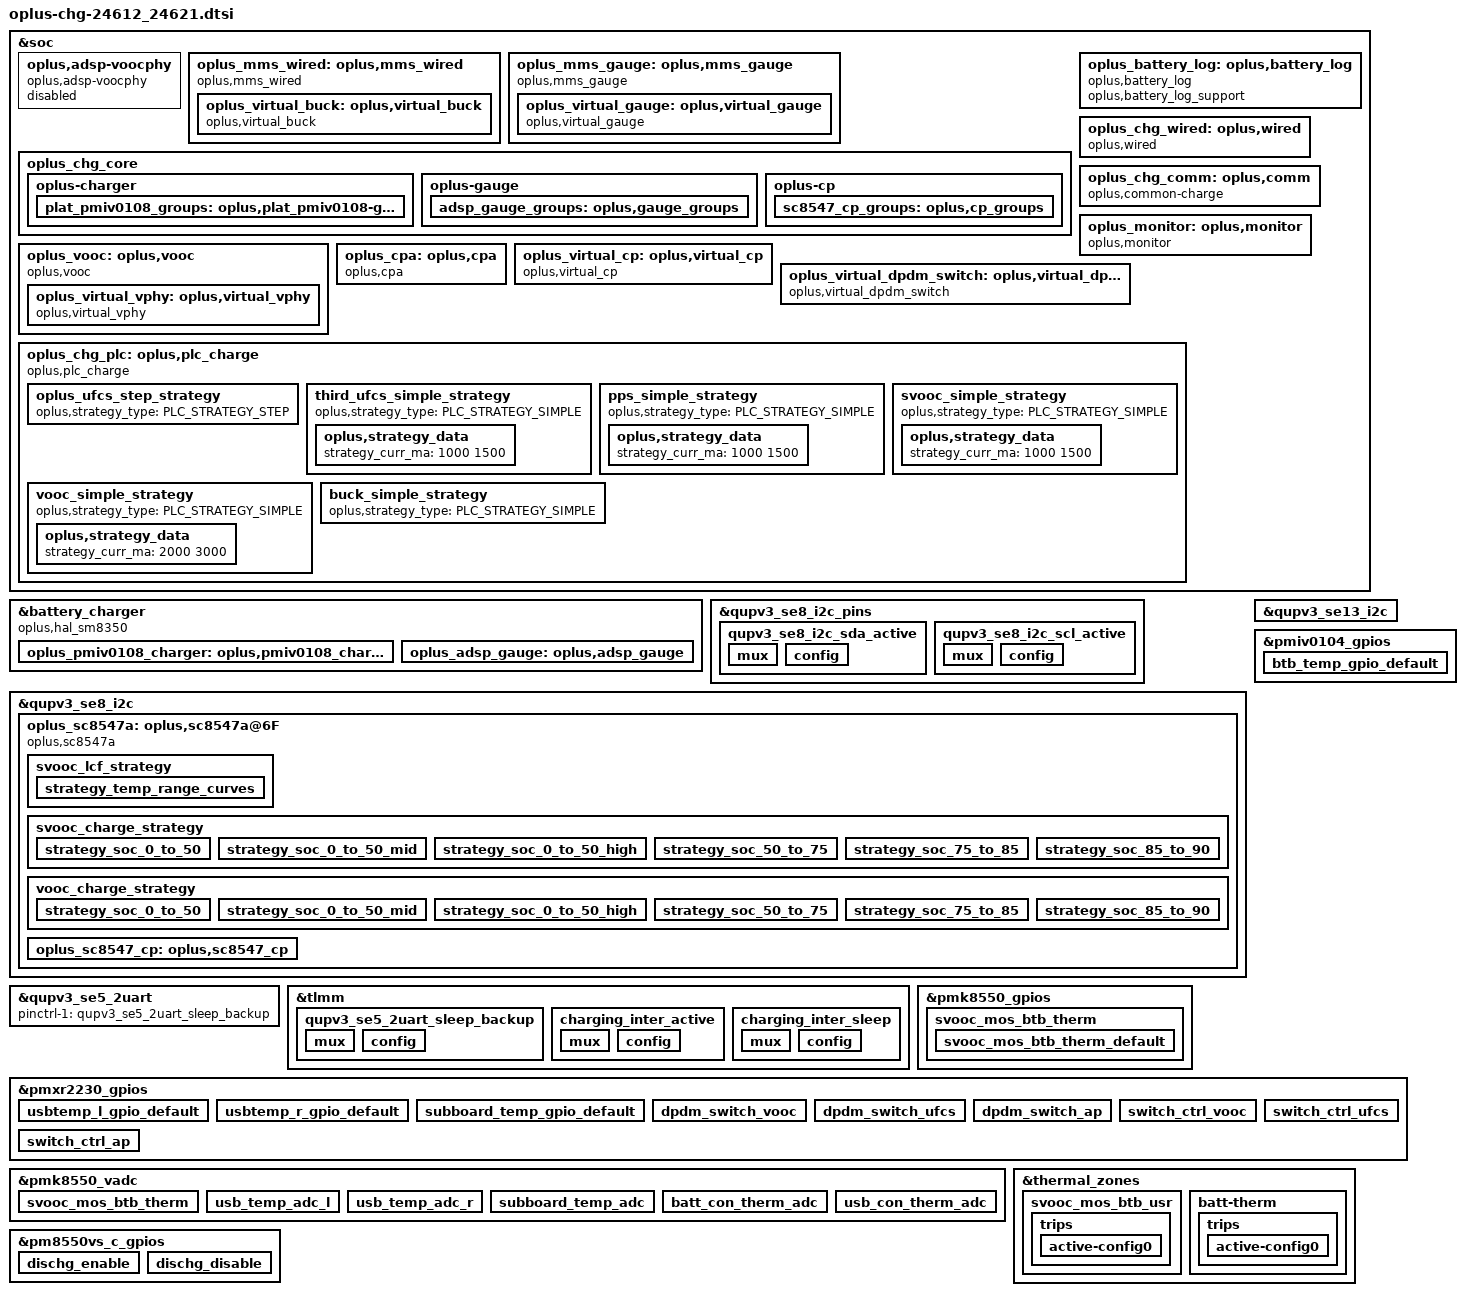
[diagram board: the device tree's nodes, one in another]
//ifdef OPLUS_FEATURE_CHG_BASIC
//BSP.CHG.Basic, 2024/10/16,  Add for charging
#include <dt-bindings/iio/qcom,spmi-adc5-gen3-pmxr2230.h>
#include <dt-bindings/iio/qcom,spmi-adc5-gen3-pmiv0104.h>
#include <dt-bindings/iio/qcom,spmi-adc5-gen3-pmk8550.h>

#include "oplus-chg-8650.h.dtsi"
#include "pps/oplus-chg-dongfeng-pps.dtsi"
#include "ufcs/oplus-chg-dongfeng-ufcs.dtsi"

&soc {
	oplus,adsp-voocphy {
		status = "disabled";
		compatible = "oplus,adsp-voocphy";
	};

	oplus_mms_wired: oplus,mms_wired {
		compatible = "oplus,mms_wired";
		oplus,buck_ic = <&oplus_virtual_buck>;
		oplus,voocphy_ic = <&oplus_virtual_vphy>;
		oplus,usbtemp_batttemp_gap = <10>;
		oplus,adc_info_name = "855";
		oplus,topic-update-interval = <5000>;

		high-temp-scheme;
		oplus,support_usbtemp_protect_v2;
		oplus_spec,usbtemp_batt_temp_low = <50>;
		oplus_spec,usbtemp_batt_temp_high = <50>;
		oplus_spec,usbtemp_batt_temp_over_hot = <60>;
		oplus_spec,usbtemp_ntc_temp_low = <57>;
		oplus_spec,usbtemp_ntc_temp_high = <69>;
		oplus_spec,usbtemp_temp_gap_low_with_batt_temp = <7>;
		oplus_spec,usbtemp_temp_gap_with_batt_temp_in_over_hot = <15>;
		oplus_spec,usbtemp_temp_gap_high_with_batt_temp = <12>;
		oplus_spec,usbtemp_temp_gap_low_without_batt_temp = <12>;
		oplus_spec,usbtemp_temp_gap_high_without_batt_temp = <24>;
		oplus_spec,usbtemp_rise_fast_temp_low = <3>;
		oplus_spec,usbtemp_rise_fast_temp_high = <3>;
		oplus_spec,usbtemp_rise_fast_temp_count_low = <30>;
		oplus_spec,usbtemp_rise_fast_temp_count_high = <20>;
		oplus_spec,usbtemp_cool_down_ntc_low = <54>;
		oplus_spec,usbtemp_cool_down_ntc_high = <65>;
		oplus_spec,usbtemp_cool_down_gap_low = <12>;
		oplus_spec,usbtemp_cool_down_gap_high = <20>;
		oplus_spec,usbtemp_cool_down_recover_ntc_low = <48>;
		oplus_spec,usbtemp_cool_down_recover_ntc_high = <60>;
		oplus_spec,usbtemp_cool_down_recover_gap_low = <6>;
		oplus_spec,usbtemp_cool_down_recover_gap_high = <15>;

		oplus_virtual_buck: oplus,virtual_buck {
			compatible = "oplus,virtual_buck";
			oplus,buck_ic = <&oplus_pmiv0108_charger>;
			oplus,buck_ic_index = <0>;
			oplus,buck_ic_connect = <OPLUS_CHG_IC_CONNECT_PARALLEL>;
			oplus,main_charger = <0>;
			oplus,buck_ic_current_ratio = <100>;
			oplus,buck_ic_func_group = <&plat_pmiv0108_groups>;

			oplus,ic_type = <OPLUS_CHG_IC_VIRTUAL_BUCK>;
			oplus,ic_index = <0>;

			oplus,uart_tx-gpio = <&tlmm 25 0x00>;
			oplus,uart_rx-gpio = <&tlmm 26 0x00>;

			oplus,dischg-gpio = <&pm8550vs_c_gpios 4 0x00>;

			pinctrl-names = "usbtemp_l_gpio_default", "usbtemp_r_gpio_default",
					"dischg_enable", "dischg_disable";
			pinctrl-0 = <&usbtemp_l_gpio_default>;
			pinctrl-1 = <&usbtemp_r_gpio_default>;
			pinctrl-2 = <&dischg_enable>;
			pinctrl-3 = <&dischg_disable>;

			io-channels = <&pmk8550_vadc PMXR2230_ADC5_GEN3_AMUX1_GPIO3_100K_PU>,
							<&pmk8550_vadc PMXR2230_ADC5_GEN3_AMUX2_GPIO4_100K_PU>;
			io-channel-names = "usb_temp_adc_l", "usb_temp_adc_r";
		};
	};

	oplus_mms_gauge: oplus,mms_gauge {
		compatible = "oplus,mms_gauge";
		oplus,gauge_ic = <&oplus_virtual_gauge>;
		oplus,voocphy_ic = <&oplus_virtual_vphy>;
		oplus,topic-update-interval = <5000>;
		oplus,support_subboard_ntc;

		oplus_virtual_gauge: oplus,virtual_gauge {
			compatible = "oplus,virtual_gauge";
			oplus,gauge_ic = <&oplus_adsp_gauge>;
			oplus,gauge_ic_index = <0>;
			oplus,gauge_ic_func_group = <&adsp_gauge_groups>;
			oplus,batt_capacity_mah = <6000>;
			oplus,ic_type = <OPLUS_CHG_IC_VIRTUAL_GAUGE>;
			oplus,ic_index = <0>;
		};
	};

	oplus_chg_core {
		oplus,chg_framework_v2;
		oplus,smart_charging_screenoff;
		oplus,chg_spec_version = <OPLUS_CHG_SPEC_VER_V3P7>;
		oplus,common-charge-icl-support;

		oplus-charger {
			plat_pmiv0108_groups: oplus,plat_pmiv0108-groups {
				functions = <
					OPLUS_IC_FUNC_INIT
					OPLUS_IC_FUNC_EXIT
					OPLUS_IC_FUNC_REG_DUMP
					OPLUS_IC_FUNC_SMT_TEST
					OPLUS_IC_FUNC_BUCK_INPUT_PRESENT
					OPLUS_IC_FUNC_BUCK_INPUT_SUSPEND
					OPLUS_IC_FUNC_BUCK_INPUT_IS_SUSPEND
					OPLUS_IC_FUNC_BUCK_OUTPUT_SUSPEND
					OPLUS_IC_FUNC_BUCK_OUTPUT_IS_SUSPEND
					OPLUS_IC_FUNC_BUCK_GET_CC_ORIENTATION
					OPLUS_IC_FUNC_BUCK_GET_CHARGER_TYPE
					OPLUS_IC_FUNC_BUCK_RERUN_BC12
					OPLUS_IC_FUNC_BUCK_QC_DETECT_ENABLE
					OPLUS_IC_FUNC_BUCK_SHIPMODE_ENABLE
					OPLUS_IC_FUNC_BUCK_SET_QC_CONFIG
					OPLUS_IC_FUNC_BUCK_SET_PD_CONFIG
					OPLUS_IC_FUNC_GET_SHUTDOWN_SOC
					OPLUS_IC_FUNC_BACKUP_SOC
					OPLUS_IC_FUNC_GET_TYPEC_MODE
					OPLUS_IC_FUNC_BUCK_SET_ICL
					OPLUS_IC_FUNC_BUCK_GET_ICL
					OPLUS_IC_FUNC_BUCK_SET_FCC
					OPLUS_IC_FUNC_BUCK_SET_FV
					OPLUS_IC_FUNC_BUCK_SET_ITERM
					OPLUS_IC_FUNC_BUCK_SET_RECHG_VOL
					OPLUS_IC_FUNC_BUCK_GET_INPUT_CURR
					OPLUS_IC_FUNC_BUCK_GET_INPUT_VOL
					OPLUS_IC_FUNC_GET_CHARGER_CYCLE
					OPLUS_IC_FUNC_BUCK_GET_VBUS_COLLAPSE_STATUS
					OPLUS_IC_FUNC_GET_OTG_ENABLE
					OPLUS_IC_FUNC_OTG_BOOST_ENABLE
					OPLUS_IC_FUNC_SET_OTG_SWITCH_STATUS
					OPLUS_IC_FUNC_GET_OTG_SWITCH_STATUS
					OPLUS_IC_FUNC_GET_OTG_ONLINE_STATUS
					OPLUS_IC_FUNC_BUCK_GET_HW_DETECT
					OPLUS_IC_FUNC_VOOCPHY_SET_MATCH_TEMP
					OPLUS_IC_FUNC_IS_OPLUS_SVID
					OPLUS_IC_FUNC_BUCK_DIS_INSERT_DETECT
					OPLUS_IC_FUNC_GET_TYPEC_ROLE
					OPLUS_IC_FUNC_SET_TYPEC_MODE
					OPLUS_IC_FUNC_BUCK_GET_USB_BTB_TEMP
					OPLUS_IC_FUNC_BUCK_GET_BATT_BTB_TEMP
				>;
				virqs = <
					OPLUS_IC_VIRQ_ERR
					OPLUS_IC_VIRQ_CC_DETECT
					OPLUS_IC_VIRQ_PLUGIN
					OPLUS_IC_VIRQ_CC_CHANGED
					OPLUS_IC_VIRQ_SUSPEND_CHECK
					OPLUS_IC_VIRQ_CHG_TYPE_CHANGE
					OPLUS_IC_VIRQ_OTG_ENABLE
					OPLUS_IC_VIRQ_SVID
				>;
			};
		};

		oplus-gauge {
			adsp_gauge_groups: oplus,gauge_groups {
				functions = <
					OPLUS_IC_FUNC_INIT
					OPLUS_IC_FUNC_EXIT
					OPLUS_IC_FUNC_REG_DUMP
					OPLUS_IC_FUNC_SMT_TEST
					OPLUS_IC_FUNC_GAUGE_GET_BATT_VOL
					OPLUS_IC_FUNC_GAUGE_GET_BATT_MAX
					OPLUS_IC_FUNC_GAUGE_GET_BATT_MIN
					OPLUS_IC_FUNC_GAUGE_GET_BATT_CURR
					OPLUS_IC_FUNC_GAUGE_GET_BATT_TEMP
					OPLUS_IC_FUNC_GAUGE_GET_BATT_SOC
					OPLUS_IC_FUNC_GAUGE_GET_BATT_FCC
					OPLUS_IC_FUNC_GAUGE_GET_BATT_CC
					OPLUS_IC_FUNC_GAUGE_GET_BATT_RM
					OPLUS_IC_FUNC_GAUGE_GET_BATT_SOH
					OPLUS_IC_FUNC_GAUGE_GET_BATT_HMAC
					OPLUS_IC_FUNC_GAUGE_GET_BATT_AUTH
					OPLUS_IC_FUNC_GAUGE_SET_BATT_FULL
					OPLUS_IC_FUNC_GAUGE_UPDATE_DOD0
					OPLUS_IC_FUNC_GAUGE_UPDATE_SOC_SMOOTH
					OPLUS_IC_FUNC_GAUGE_GET_CB_STATUS
					OPLUS_IC_FUNC_GAUGE_GET_BATT_NUM
					OPLUS_IC_FUNC_GAUGE_GET_DEVICE_TYPE
					OPLUS_IC_FUNC_GAUGE_GET_DEVICE_TYPE_FOR_VOOC
					OPLUS_IC_FUNC_GAUGE_GET_BATT_FCC
					OPLUS_IC_FUNC_GAUGE_UPDATE
					OPLUS_IC_FUNC_GAUGE_IS_SUSPEND
					OPLUS_IC_FUNC_GAUGE_GET_SUBBOARD_TEMP
					OPLUS_IC_FUNC_GAUGE_GET_BCC_PARMS
					OPLUS_IC_FUNC_GAUGE_GET_DEVICE_TYPE_FOR_BCC
					OPLUS_IC_FUNC_GAUGE_GET_DOD0
					OPLUS_IC_FUNC_GAUGE_GET_DOD0_PASSED_Q
					OPLUS_IC_FUNC_GAUGE_GET_QMAX
					OPLUS_IC_FUNC_GAUGE_GET_QMAX_PASSED_Q
				>;
				virqs = <
					OPLUS_IC_VIRQ_ERR
					OPLUS_IC_VIRQ_OFFLINE
					OPLUS_IC_VIRQ_RESUME
				>;
			};
		};

		oplus-cp {
			sc8547_cp_groups: oplus,cp_groups {
			functions = <
					OPLUS_IC_FUNC_INIT
					OPLUS_IC_FUNC_EXIT
					OPLUS_IC_FUNC_REG_DUMP
					OPLUS_IC_FUNC_SMT_TEST
					OPLUS_IC_FUNC_CP_ENABLE
					OPLUS_IC_FUNC_CP_HW_INTI
					OPLUS_IC_FUNC_CP_SET_WORK_START
					OPLUS_IC_FUNC_CP_CHECK_WORK_MODE_SUPPORT
					OPLUS_IC_FUNC_CP_SET_WORK_MODE
					OPLUS_IC_FUNC_CP_GET_WORK_MODE
					OPLUS_IC_FUNC_CP_GET_VIN
					OPLUS_IC_FUNC_CP_GET_IIN
					OPLUS_IC_FUNC_CP_SET_IIN
					OPLUS_IC_FUNC_CP_GET_VOUT
					OPLUS_IC_FUNC_CP_GET_IOUT
					OPLUS_IC_FUNC_CP_GET_VAC
					OPLUS_IC_FUNC_CP_GET_WORK_STATUS
					OPLUS_IC_FUNC_CP_SET_ADC_ENABLE
					OPLUS_IC_FUNC_CP_WATCHDOG_ENABLE
					OPLUS_IC_FUNC_CP_SET_UCP_DISABLE
				>;
				virqs = <
					OPLUS_IC_VIRQ_ERR
					OPLUS_IC_VIRQ_ONLINE
					OPLUS_IC_VIRQ_OFFLINE
				>;
			};
		};
	};

	oplus_battery_log: oplus,battery_log {
		compatible = "oplus,battery_log";

		oplus,battery_log_support;
	};

	oplus_chg_wired: oplus,wired {
		compatible = "oplus,wired";

		oplus,vooc-support;

		oplus_spec,vbatt_pdqc_to_5v_thr = <5000>;
		oplus_spec,vbatt_pdqc_to_9v_thr = <5000>;
		oplus_spec,pd-iclmax-ma = <1500>;
		oplus_spec,qc-iclmax-ma = <1500>;
		oplus_spec,non-standard-ibatmax-ma = <500>;
		oplus_spec,input-power-mw = <
			2500		/* OPLUS_WIRED_CHG_MODE_UNKNOWN */
			2500		/* OPLUS_WIRED_CHG_MODE_SDP */
			7500		/* OPLUS_WIRED_CHG_MODE_CDP */
			10000		/* OPLUS_WIRED_CHG_MODE_DCP */
			15000		/* OPLUS_WIRED_CHG_MODE_VOOC */
			13500		/* OPLUS_WIRED_CHG_MODE_QC */
			13500		/* OPLUS_WIRED_CHG_MODE_PD */
		>;
		oplus_spec,led_on-fccmax-ma = <0 1140 4000 4000 4000 4000 4000 1000 0>;
		oplus_spec,fccmax-ma-lv = <
			0 879  2200 2200 2200 2200 2200 2200 0	/* OPLUS_WIRED_CHG_MODE_UNKNOWN */
			0 600  600  600  600  600  600  600  0	/* OPLUS_WIRED_CHG_MODE_SDP */
			0 879  1600 1600 1600 1600 1600 1600 0	/* OPLUS_WIRED_CHG_MODE_CDP */
			0 879  2200 2200 2200 2200 2200 2200 0	/* OPLUS_WIRED_CHG_MODE_DCP */
			0 879  2200 2200 2200 2200 2200 2200 0	/* OPLUS_WIRED_CHG_MODE_VOOC */
			0 879  3000 3000 3000 3000 3000 3000 0	/* OPLUS_WIRED_CHG_MODE_QC */
			0 879  3000 3000 3000 3000 3000 3000 0	/* OPLUS_WIRED_CHG_MODE_PD */
		>;
		oplus_spec,fccmax-ma-hv = <
			0 879  2200 2200 2200 2200 2200 2200 0	/* OPLUS_WIRED_CHG_MODE_UNKNOWN */
			0 600  600  600  600  600  600  600  0	/* OPLUS_WIRED_CHG_MODE_SDP */
			0 879  1600 1600 1600 1600 1600 1600 0	/* OPLUS_WIRED_CHG_MODE_CDP */
			0 879  2200 2200 2200 2200 2200 2200 0	/* OPLUS_WIRED_CHG_MODE_DCP */
			0 879  2200 2200 2200 2200 2200 2200 0	/* OPLUS_WIRED_CHG_MODE_VOOC */
			0 879  2637 3000 3000 3000 3000 3000 0	/* OPLUS_WIRED_CHG_MODE_QC */
			0 879  2637 3000 3000 3000 3000 3000 0	/* OPLUS_WIRED_CHG_MODE_PD */
		>;

		oplus_spec,cool_down_pdqc_vol_mv = <5000 5000 5000 9000>;
		oplus_spec,cool_down_pdqc_curr_ma = <1200 1500 2000 1500>;
		oplus_spec,cool_down_vooc_curr_ma = <1200 1500 2000 2500 3000 3000>;
		oplus_spec,cool_down_normal_curr_ma = <1200 1500 2000>;

		oplus_spec,vbus_ov_thr_mv = <10500 10500>;
		oplus_spec,vbus_uv_thr_mv = <4300 4300>;

		/* first data is strategy used temp type */
		oplus,vooc_strategy_name = "cgcl";
		oplus,vooc_strategy_data = <OPLUS_STRATEGY_USE_BATT_TEMP
					    0   345 3200 1 0
					    345 370 3000 2 0
					    370 385 2200 2 1>;
	};

	oplus_chg_comm: oplus,comm {
		compatible = "oplus,common-charge";
		oplus_spec,batt-them-thr = <(-100) 0 50 120 160 350 450 530>;
		oplus_spec,iterm-ma = <303>; /* 5860*0.05+10 */
		oplus_spec,removed_bat_decidegc = <390>; /*-39 degree*/
		oplus_spec,fv-mv = <4490 4490 4490 4490 4490 4490 4470 4130 4130>;
		oplus_spec,sw-fv-mv = <4440 4440 4440 4440 4440 4440 4420 4080 4080>;
		oplus_spec,hw-fv-inc-mv = <0 18 18 18 18 18 18 18 0>;
		oplus_spec,sw-over-fv-mv = <4500 4500 4500 4500 4500 4500 4480 4140 4140>;
		oplus_spec,sw-over-fv-dec-mv = <8>;
		oplus_spec,non-standard-sw-fv-mv = <3930>;
		oplus_spec,non-standard-fv-mv = <3980>;
		oplus_spec,non-standard-hw-fv-inc-mv = <18>;
		oplus_spec,non-standard-sw-over-fv-mv = <3990>;
		oplus_spec,non-standard-vbatdet-mv = <3680>;
		oplus_spec,wired-vbatdet-mv = <0 4190 4290 4390 4390 4390 4370 4030 0>;
		oplus_spec,fcc-gear-thr-mv = <4180>;
		oplus_spec,fcc-gear-shake-mv = <500 500 500 400 300 200 200 200 200>;
		oplus_spec,vbatt-ov-thr-mv = <4600>;

		oplus_spec,full_pre_ffc_judge;
		oplus_spec,full-pre-ffc-mv = <4485>;
		oplus_spec,ffc-temp-thr = <120 210 350 440>;
		oplus_spec,wired-ffc-step-max = <2>;
		oplus_spec,wired-ffc-fv-mv = <4630 4630>;

		oplus_spec,wired-ffc-fv-cutoff-mv = <4545 4545 4520 4545 4545 4495>;
		oplus_spec,wired-ffc-fcc-ma = <1500 1500 1500 1400 1400 1000>;
		oplus_spec,wired-ffc-fcc-cutoff-ma = <1300 1300 1300 1300 1300 900>;

		oplus_spec,vbat_uv_thr_mv = <3300>;
		oplus_spec,vbat_charging_uv_thr_mv = <3200>;

		/*If use subboard NTC as battery temp, config it as 20, otherwise 0 */
		oplus_spec,tbatt_power_off_cali_temp = <0>;
		oplus_spec,poweroff_high_batt_temp = <720>;
		oplus_spec,poweroff_emergency_batt_temp = <770>;
		oplus,vooc_show_ui_soc_decimal;
		oplus,ui_soc_decimal_speedmin = <20>;
		oplus,gauge_stuck_jump_support;
		oplus,gauge_stuck_threshold = <15>;
		oplus,gauge_stuck_time = <50>;
		oplus,smooth_switch;
		oplus,reserve_chg_soc = <1>;
	};

	oplus_monitor: oplus,monitor {
		compatible = "oplus,monitor";
		oplus,topic-update-interval = <60000>;

		track,fast_chg_break_t_thd = <1000>;
		track,general_chg_break_t_thd = <200>;
		track,voocphy_type = <TRACK_AP_SINGLE_CP_VOOCPHY>;
		track,wired_max_power = <45000>;
		track,wired_fast_chg_scheme = <2>;
	};

	oplus_vooc: oplus,vooc {
		compatible = "oplus,vooc";
		oplus,vooc_ic = <&oplus_virtual_vphy>;

		oplus_spec,vooc_soc_range = <50 75 85>;
		oplus_spec,vooc_temp_range = <50 120 180 350 450>;

		oplus,vooc_data_width = <7>;
		oplus,vooc_curr_max = <CP_CURR_LIMIT_7BIT_9_0A>; /* 45W: 11V 4.1A(IBUS *2) */
		oplus,vooc_power_max_w = <45>;
		oplus,vooc_project = <VOOC_PROJECT_OTHER>;
		oplus,vooc_curr_table_type = <VOOC_CP_CURR_TABLE>;
		oplus,voocphy_support = <2>; /* TRACK_AP_SINGLE_CP_VOOCPHY */
		oplus,support_fake_vooc_check;
		oplus,subboard_ntc_abnormal_current = <4000>;

		oplus,abnormal_adapter_current = <CURR_LIMIT_7BIT_7_5A CURR_LIMIT_7BIT_7_5A
						CURR_LIMIT_7BIT_5_0A CURR_LIMIT_7BIT_5_0A
						CURR_LIMIT_7BIT_4_0A CURR_LIMIT_7BIT_4_0A
						CURR_LIMIT_7BIT_3_0A CURR_LIMIT_7BIT_3_0A
						CURR_LIMIT_7BIT_2_0A CURR_LIMIT_7BIT_2_0A>;

		/* first data is strategy used temp type */
		oplus,general_strategy_name = "cgcl";
		oplus,general_strategy_data = < OPLUS_STRATEGY_USE_SHELL_TEMP
						0   400 CURR_LIMIT_7BIT_7_5A 1 0
						390 420 CURR_LIMIT_7BIT_5_0A 2 0
						410 430 CURR_LIMIT_7BIT_4_0A 3 1
						420 440 CURR_LIMIT_7BIT_3_0A 3 2 >;

		oplus,plc_strategy-data = <&buck_simple_strategy &svooc_simple_strategy &vooc_simple_strategy>;
		oplus,plc_strategy-names = "default", "svooc", "vooc";

		oplus_virtual_vphy: oplus,virtual_vphy {
			compatible = "oplus,virtual_vphy";
			oplus,vphy_ic = <&oplus_sc8547a>;
			oplus,dpdm_switch_ic = <&oplus_virtual_dpdm_switch>;

			oplus,ic_type = <OPLUS_CHG_IC_VIRTUAL_VPHY>;
			oplus,ic_index = <0>;
		};
	};

	oplus_cpa: oplus,cpa {
		compatible = "oplus,cpa";
		/* format: <protocol_type power_w> */
		oplus,protocol_list = <CHG_PROTOCOL_UFCS  33
				       CHG_PROTOCOL_VOOC 45
				       CHG_PROTOCOL_PPS  33
				       CHG_PROTOCOL_PD   15
				       CHG_PROTOCOL_QC   15>;
		oplus,default_protocol_list = <CHG_PROTOCOL_UFCS
                                               CHG_PROTOCOL_VOOC
                                               CHG_PROTOCOL_PPS
					       CHG_PROTOCOL_PD>;
	};

	oplus_virtual_cp: oplus,virtual_cp {
		compatible = "oplus,virtual_cp";

		oplus,ic_type = <OPLUS_CHG_IC_VIRTUAL_CP>;
		oplus,ic_index = <0>;

		oplus,cp_ic = <&oplus_sc8547_cp>;
		oplus,input_curr_max_ma = <5000>;

		oplus,cp_ic_connect = <OPLUS_CHG_IC_CONNECT_PARALLEL>;
		oplus,main_cp = <0>;

		oplus,reg_proc_node;
	};

	oplus_virtual_dpdm_switch: oplus,virtual_dpdm_switch {
		compatible = "oplus,virtual_dpdm_switch";

		oplus,ic_type = <OPLUS_CHG_IC_MISC>;
		oplus,ic_index = <0>;

		oplus,dpdm_switch1-gpio = <&pmxr2230_gpios 8 0x00>;
		oplus,switch_ctrl-gpio = <&pmxr2230_gpios 12 0x00>;
		pinctrl-names = "switch_ctrl_ap", "switch_ctrl_vooc", "switch_ctrl_ufcs",
				"dpdm_switch_ap", "dpdm_switch_vooc", "dpdm_switch_ufcs";
		pinctrl-0 = <&switch_ctrl_ap>;
		pinctrl-1 = <&switch_ctrl_vooc>;
		pinctrl-2 = <&switch_ctrl_ufcs>;
		pinctrl-3 = <&dpdm_switch_ap>;
		pinctrl-4 = <&dpdm_switch_vooc>;
		pinctrl-5 = <&dpdm_switch_ufcs>;
	};
};

&battery_charger {
	//for oplus chg framework:
	oplus,chg_ops = "plat-pmic";
	qcom,pmic_ftm_vph = "/sys/bus/spmi/drivers/pmic-spmi/0-00/c42d000.qcom,spmi:qcom,pmk8550@0:vadc@9000/iio:device0/in_voltage_pm8550b_vph_pwr_input";
	qcom,pmic_ftm_vbat = "/sys/bus/spmi/drivers/pmic-spmi/0-00/c42d000.qcom,spmi:qcom,pmk8550@0:vadc@9000/iio:device0/in_voltage_pm8550b_vbat_sns_qbg_input";
};

&battery_charger {
	//for oplus chg framework:
	compatible = "oplus,hal_sm8350";

	pinctrl-names = "subboard_temp_gpio_default", "btb_temp_gpio_default";
	pinctrl-0 = <&subboard_temp_gpio_default>;
	pinctrl-1 = <&btb_temp_gpio_default>;

	qcom,otg_boost_src = <0>;//0:plat_pmic 1:external
	oplus,batt_num = <1>;
	oplus,otg_scheme = <0>;//0:cid 1:ccdetect_gpio 2:switch

	/* QCOM QBG full param, depend on adapter type and temp_region */
	oplus,batt_full_method_new;
	oplus,batt_full_temp = <(-100) 120 210 440>;
	oplus,batt_full_para = <1000 1000 1000 1000      /* normal pd qc */
				1000 300 1000 1800      /* svooc */
				1000 300 1000 1351      /* oplus ufcs */
				1000 80 400 1351      /* oplus pps */
				1000 300 1000 1351      /* third ufcs */
				1000 80 400 1351      /* third pps */
				400 400 400 400>;    /* ffc */

	oplus_pmiv0108_charger: oplus,pmiv0108_charger {
		oplus,ic_type = <OPLUS_CHG_IC_BUCK>;
		oplus,ic_index = <0>;
	};
	oplus_adsp_gauge: oplus,adsp_gauge {
		oplus,ic_type = <OPLUS_CHG_IC_GAUGE>;
		oplus,ic_index = <0>;
	};

};

&battery_charger {
	io-channels = <&pmk8550_vadc PMXR2230_ADC5_GEN3_AMUX3_GPIO7_100K_PU>,
					<&pmk8550_vadc PMIV0104_ADC5_GEN3_AMUX_THM6_GPIO6_100K_PU>,
					<&pmk8550_vadc PMIV0104_ADC5_GEN3_AMUX_THM4_USB_THERM_100K_PU>;
	io-channel-names = "subboard_temp_adc", "batt_con_therm_adc", "usb_con_therm_adc";
};

&qupv3_se8_i2c_pins {
	qupv3_se8_i2c_sda_active: qupv3_se8_i2c_sda_active {
		mux {
			pins = "gpio36";
			function = "qup1_se1_l0";
		};

		config {
			pins = "gpio36";
			drive-strength = <2>;
			bias-pull-up;
			qcom,i2c_pull;
		};
	};

	qupv3_se8_i2c_scl_active: qupv3_se8_i2c_scl_active {
		mux {
			pins = "gpio37";
			function = "qup1_se1_l1";
		};

		config {
			pins = "gpio37";
			drive-strength = <2>;
			bias-pull-up;
			qcom,i2c_pull;
		};
	};
};

&qupv3_se8_i2c {
	status = "okay";
	qcom,clk-freq-out = <400000>;
	pinctrl-0 = <&qupv3_se8_i2c_sda_active>, <&qupv3_se8_i2c_scl_active>;

	oplus_sc8547a:oplus,sc8547a@6F {
		status = "okay";
		compatible = "oplus,sc8547a";
		reg = <0x6F>;

		oplus,use_vooc_phy;
		oplus,use_ufcs_phy;
		oplus,vac_support;
		oplus_spec,irq_gpio = <&tlmm 125 0x00>;
		pinctrl-names = "charging_inter_active", "charging_inter_sleep";
		pinctrl-0 = <&charging_inter_active>;
		pinctrl-1 = <&charging_inter_sleep>;

		oplus,ic_type = <OPLUS_CHG_IC_VPHY>;
		oplus,ic_index = <0>;
		oplus,vooc-version = <VOOC_VERSION_5_0>;

		ocp_reg = <0xb>;
		ovp_reg = <0x36>;
		oplus_spec,slave_cp_enable_thr = <1400>;		//2000-100mA
		oplus_spec,slave_cp_disable_thr_high = <1100>;	//1500+100mA
		oplus_spec,voocphy_current_default = <41>;

		oplus_spec,svooc_cool_down_current_limit = <82 20 20 24 30 34 40 44 50 54 60 64 70 74>;
		oplus_spec,vooc_cool_down_current_limit = <30 20 20 24 30 34 40 44 50 54 60 64 70 74>;

		oplus_spec,impedance_calculation_newmethod;
		oplus_spec,svooc_circuit_r_l = <0x18>;
		oplus_spec,svooc_circuit_r_h = <0x2>;/* 65 mR */
		oplus_spec,vooc_multistep_initial_batt_temp = <1000>;
		oplus_spec,vooc_little_cool_temp = <160>;
		oplus_spec,vooc_little_cool_high_temp = <210>;
		oplus_spec,vooc_cool_temp = <120>;
		oplus_spec,vooc_little_cold_temp = <50>;
		oplus_spec,vooc_normal_low_temp = <350>;
		oplus_spec,vooc_strategy_normal_current = <122>;
		oplus_spec,vooc_normal_to_little_cool_current = <100>;
		oplus_spec,vooc_over_high_temp = <510>;
		oplus_spec,vooc_low_temp = <0>;

		oplus_spec,vooc_high_temp = <500>;
		oplus_spec,vooc_low_soc = <0>;
		oplus_spec,vooc_high_soc = <95>;
		oplus_spec,vooc_normal_high_temp = <440>;
		oplus_spec,vooc_warm_vol_thr = <4000>;
		oplus_spec,vooc_warm_soc_thr = <50>;

		oplus_spec,vooc_strategy1_batt_high_temp0 = <385>;
		oplus_spec,vooc_strategy1_batt_high_temp1 = <395>;
		oplus_spec,vooc_strategy1_batt_high_temp2 = <420>;
		oplus_spec,vooc_strategy1_batt_low_temp2 = <410>;
		oplus_spec,vooc_strategy1_batt_low_temp1 = <385>;
		oplus_spec,vooc_strategy1_batt_low_temp0 = <375>;

		oplus_spec,vooc_strategy1_high_current0 = <80>;
		oplus_spec,vooc_strategy1_high_current1 = <61>;
		oplus_spec,vooc_strategy1_high_current2 = <40>;
		oplus_spec,vooc_strategy1_low_current2 = <40>;
		oplus_spec,vooc_strategy1_low_current1 = <61>;
		oplus_spec,vooc_strategy1_low_current0 = <80>;

		oplus_spec,vooc_strategy1_high_current0_vooc = <60>;
		oplus_spec,vooc_strategy1_high_current1_vooc = <50>;
		oplus_spec,vooc_strategy1_high_current2_vooc = <45>;
		oplus_spec,vooc_strategy1_low_current2_vooc = <45>;
		oplus_spec,vooc_strategy1_low_current1_vooc = <50>;
		oplus_spec,vooc_strategy1_low_current0_vooc = <60>;

		oplus_spec,voocphy_req_freq = <1804800 2073600 2208000 3302400>;
		oplus_spec,voocphy_freq_mincore = <1804800>;
		oplus_spec,voocphy_freq_midcore = <2073600>;
		oplus_spec,voocphy_freq_maxcore = <2208000>;
		oplus_spec,voocphy_current_change_timeout = <100>;
		oplus_spec,copycat_vooc_support;

		oplus_spec,voocphy_ibat_over_current = <9600>;
		oplus_spec,voocphy_svooc_cp_max_ibus = <4500>;
		oplus_spec,voocphy_vooc_cp_max_ibus = <4500>;
		oplus_spec,voocphy_cp_max_ibus = <4500>;

		oplus_spec,vooc_little_cold_full_voltage = <4500>;
		oplus_spec,vooc_cool_full_voltage = <4500>;
		oplus_spec,vooc_little_cool_full_voltage = <4550>;
		oplus_spec,vooc_little_cool_high_full_voltage = <4550>;
		oplus_spec,vooc_warm_full_voltage = <4130>;
		oplus_spec,vooc_1time_full_voltage = <4560>;
		oplus_spec,vooc_ntime_full_voltage = <4550>;
		oplus_spec,low_curr_full_t1 = <120>;
		oplus_spec,low_curr_full_t2 = <350>;
		oplus_spec,low_curr_full_t3 = <430>;

		svooc_batt_sys_curve = <0 1 0 1 0 0 0	// 4000mA
					1 1 1 1 0 0 0	// 4604mV
					0 0 1 1 0 1 0	// 2600mA
					1 1 1 1 0 0 0	// 4604mV
					0 0 0 1 0 1 1	// 1100mA
					1 1 1 1 0 0 0>;	// 4604mV

		vooc_batt_sys_curve =  <0 1 0 1 0 0 0	// 4000mA
					1 1 1 1 0 0 0	// 4604mV
					0 0 1 1 0 1 0	// 2600mA
					1 1 1 1 0 0 0	// 4604mV
					0 0 0 1 0 1 1	// 1100mA
					1 1 1 1 0 0 0>;	// 4604mV

		oplus_spec,soc_range = <0 20 35 55 75 85 95>;

		svooc_lcf_strategy {
			oplus,temp_type = <OPLUS_STRATEGY_USE_SHELL_TEMP>;
			oplus,temp_range = <0 50 120 160 210 380 440>;

			strategy_temp_range_curves {
				strategy_temp_range_t0 = <300 4500 0
								 275 4490 0
								 250 4480 0
								 225 4470 0
								 200 4460 1>;
				strategy_temp_range_t1 = <300 4500 0
								 265 4495 0
								 230 4480 0
								 195 4470 0
								 160 4460 1>;
				strategy_temp_range_t2 = <850 4550 0
								 800 4545 0
								 700 4530 0
								 600 4520 0
								 450 4510 1>;
				strategy_temp_range_t3 = <1350 4550 0
								 1300 4545 0
								 1200 4530 0
								 1100 4520 0
								 950 4510 1>;
				strategy_temp_range_t4 = <1350 4550 0
								 1300 4545 0
								 1200 4530 0
								 1100 4520 0
								 950 4510 1>;
				strategy_temp_range_t5 = <2100 4550 0
								 2050 4545 0
								 1950 4530 0
								 1850 4520 0
								 1700 4510 1>;
			};
		};

		svooc_charge_strategy {
			strategy_soc_0_to_50 { /* 0 ~ 20 */
				strategy_temp_little_cold =	<4150 19 0 0 0
								 4150 15 0 0 0
								 4490 13 0 0 0
								 4500 10 1 0 0>;
				strategy_temp_cool =	<4150 28 0 0 0
								 4150 25 0 0 0
								 4150 20 0 0 0
								 4490 19 0 0 0
								 4490 15 0 0 0
								 4500 10 1 0 0>;
				strategy_temp_little_cool =	<4150 41 0 60 0
								 4150 40 0 0 0
								 4150 35 0 0 0
								 4510 33 0 0 0
								 4510 30 0 600 0
								 4510 25 0 600 0
								 4540 22 0 0 0
								 4540 20 0 0 0
								 4540 15 0 0 0
								 4550 10 1 0 0>;
				strategy_temp_little_cool_high = <4230 41 0 60 0
								 4230 40 0 0 0
								 4230 35 0 0 0
								 4510 33 0 0 0
								 4510 30 0 600 0
								 4510 25 0 600 0
								 4540 22 0 0 0
								 4540 20 0 0 0
								 4540 15 0 0 0
								 4550 10 1 0 0>;
				strategy_temp_normal_low =	<4230 41 0 60 0
								 4230 40 0 0 0
								 4230 35 0 0 0
								 4510 33 0 0 0
								 4510 30 0 600 0
								 4510 25 0 600 0
								 4540 22 0 0 0
								 4540 20 0 0 0
								 4540 15 0 0 0
								 4550 10 1 0 0>;
				strategy_temp_normal_high =	<4230 41 0 60 0
								 4230 40 0 0 0
								 4230 35 0 0 0
								 4510 33 0 0 0
								 4510 30 0 600 0
								 4510 25 0 600 0
								 4540 22 0 0 0
								 4540 20 0 0 0
								 4540 15 0 0 0
								 4550 11 1 0 0>;
				strategy_temp_warm = <4120 16 0 0 0
								 4120 15 0 0 0
								 4130 10 1 0 0>;
			};

			strategy_soc_0_to_50_mid { /* 21 ~ 35 */
				strategy_temp_little_cold =	<4150 19 0 0 0
								 4150 15 0 0 0
								 4490 13 0 0 0
								 4500 10 1 0 0>;
				strategy_temp_cool =	<4150 28 0 0 0
								 4150 25 0 0 0
								 4150 20 0 0 0
								 4490 19 0 0 0
								 4490 15 0 0 0
								 4500 10 1 0 0>;
				strategy_temp_little_cool =	<4150 41 0 60 0
								 4150 40 0 0 0
								 4150 35 0 0 0
								 4510 33 0 0 0
								 4510 30 0 600 0
								 4510 25 0 600 0
								 4540 22 0 0 0
								 4540 20 0 0 0
								 4540 15 0 0 0
								 4550 10 1 0 0>;
				strategy_temp_little_cool_high = <4230 41 0 60 0
								 4230 40 0 0 0
								 4230 35 0 0 0
								 4510 33 0 0 0
								 4510 30 0 600 0
								 4510 25 0 600 0
								 4540 22 0 0 0
								 4540 20 0 0 0
								 4540 15 0 0 0
								 4550 10 1 0 0>;
				strategy_temp_normal_low = <4230 41 0 60 0
								 4230 40 0 0 0
								 4230 35 0 0 0
								 4510 33 0 0 0
								 4510 30 0 600 0
								 4510 25 0 600 0
								 4540 22 0 0 0
								 4540 20 0 0 0
								 4540 15 0 0 0
								 4550 10 1 0 0>;
				strategy_temp_normal_high =	<4230 41 0 60 0
								 4230 40 0 0 0
								 4230 35 0 0 0
								 4510 33 0 0 0
								 4510 30 0 600 0
								 4510 25 0 600 0
								 4540 22 0 0 0
								 4540 20 0 0 0
								 4540 15 0 0 0
								 4550 11 1 0 0>;
				strategy_temp_warm = <4120 16 0 0 0
								 4120 15 0 0 0
								 4130 10 1 0 0>;
			};

			strategy_soc_0_to_50_high { /* 36 ~ 55 */
				strategy_temp_little_cold =	<4150 19 0 0 0
								 4150 15 0 0 0
								 4490 13 0 0 0
								 4500 10 1 0 0>;
				strategy_temp_cool = <4150 25 0 0 0
								 4150 20 0 0 0
								 4490 19 0 0 0
								 4490 15 0 0 0
								 4500 10 1 0 0>;
				strategy_temp_little_cool =	<4510 30 0 0 0
								 4510 25 0 0 0
								 4540 22 0 0 0
								 4540 20 0 0 0
								 4540 15 0 0 0
								 4550 10 1 0 0>;
				strategy_temp_little_cool_high = <4510 30 0 0 0
								 4510 25 0 0 0
								 4540 22 0 0 0
								 4540 20 0 0 0
								 4540 15 0 0 0
								 4550 10 1 0 0>;
				strategy_temp_normal_low =	<4230 41 0 60 0
								 4230 40 0 0 0
								 4230 35 0 0 0
								 4510 33 0 0 0
								 4510 30 0 600 0
								 4510 25 0 600 0
								 4540 22 0 0 0
								 4540 20 0 0 0
								 4540 15 0 0 0
								 4550 10 1 0 0>;
				strategy_temp_normal_high =	<4230 41 0 60 0
								 4230 40 0 0 0
								 4230 35 0 0 0
								 4510 33 0 0 0
								 4510 30 0 600 0
								 4510 25 0 600 0
								 4540 22 0 0 0
								 4540 20 0 0 0
								 4540 15 0 0 0
								 4550 10 1 0 0>;
				strategy_temp_warm = <4120 16 0 0 0
								 4120 15 0 0 0
								 4130 10 1 0 0>;
			};

			strategy_soc_50_to_75 { /* 56 ~ 75 */
				strategy_temp_little_cold =	<4500 10 1 0 0>;
				strategy_temp_cool =	<4490 15 0 0 0
								 4500 10 1 0 0>;
				strategy_temp_little_cool =	<4540 20 0 0 0
								 4540 15 0 0 0
								 4550 10 1 0 0>;
				strategy_temp_little_cool_high = <4540 20 0 0 0
								 4540 15 0 0 0
								 4550 10 1 0 0>;
				strategy_temp_normal_low =	<4510 25 0 0 0
								 4540 22 0 0 0
								 4540 20 0 0 0
								 4540 15 0 0 0
								 4550 10 1 0 0>;
				strategy_temp_normal_high =	<4510 25 0 0 0
								 4540 22 0 0 0
								 4540 20 0 0 0
								 4540 15 0 0 0
								 4550 11 1 0 0>;
				strategy_temp_warm = <4130 10 1 0 0>;
			};

			strategy_soc_75_to_85 {	/*76 ~ 85*/
				strategy_temp_little_cold =	<4500 10 1 0 0>;
				strategy_temp_cool =	<4500 10 1 0 0>;
				strategy_temp_little_cool =	<4540 15 0 0 0
								 4550 10 1 0 0>;
				strategy_temp_little_cool_high = <4540 15 0 0 0
								 4550 10 1 0 0>;
				strategy_temp_normal_low =	<4540 15 0 0 0
								 4550 10 1 0 0>;
				strategy_temp_normal_high =	<4540 15 0 0 0
								 4550 11 1 0 0>;
				strategy_temp_warm = <4130 10 1 0 0>;
			};

			strategy_soc_85_to_90 { /*86 ~ 95*/
				strategy_temp_little_cold =	<4500 10 1 0 0>;
				strategy_temp_cool =	<4500 10 1 0 0>;
				strategy_temp_little_cool =	<4550 10 1 0 0>;
				strategy_temp_little_cool_high = <4550 10 1 0 0>;
				strategy_temp_normal_low =	<4550 10 1 0 0>;
				strategy_temp_normal_high =	<4550 10 1 0 0>;
				strategy_temp_warm = <4130 10 1 0 0>;
			};
		};

		vooc_charge_strategy {
			strategy_soc_0_to_50 { /* 0 ~ 20 */
				strategy_temp_little_cold =	<4150 30 0 0 0
								 4490 26 0 0 0
								 4500 20 1 0 0>;
				strategy_temp_cool = <4490 30 0 0 0
								 4500 20 1 0 0>;
				strategy_temp_little_cool =	<4540 30 0 0 0
								 4550 20 1 0 0>;
				strategy_temp_little_cool_high = <4540 30 0 0 0
								 4550 20 1 0 0>;
				strategy_temp_normal_low =	<4540 30 0 0 0
								 4550 20 1 0 0>;
				strategy_temp_normal_high =	<4540 30 0 0 0
								 4550 20 1 0 0>;
				strategy_temp_warm = <4120 26 0 0 0
								 4130 20 1 0 0>;
			};

			strategy_soc_0_to_50_mid { /* 21 ~ 35 */
				strategy_temp_little_cold =	<4150 30 0 0 0
								 4490 26 0 0 0
								 4500 20 1 0 0>;
				strategy_temp_cool = <4490 30 0 0 0
								 4500 20 1 0 0>;
				strategy_temp_little_cool =	<4540 30 0 0 0
								 4550 20 1 0 0>;
				strategy_temp_little_cool_high = <4540 30 0 0 0
								 4550 20 1 0 0>;
				strategy_temp_normal_low =	<4540 30 0 0 0
								 4550 20 1 0 0>;
				strategy_temp_normal_high =	<4540 30 0 0 0
								 4550 22 1 0 0>;
				strategy_temp_warm = <4120 30 0 0 0
								 4130 20 1 0 0>;
			};

			strategy_soc_0_to_50_high { /* 36 ~ 55 */
				strategy_temp_little_cold =	<4150 30 0 0 0
								 4490 26 0 0 0
								 4500 20 1 0 0>;
				strategy_temp_cool = <4490 30 0 0 0
								 4500 20 1 0 0>;
				strategy_temp_little_cool =	<4540 30 0 0 0
								 4550 20 1 0 0>;
				strategy_temp_little_cool_high = <4540 30 0 0 0
								 4550 20 1 0 0>;
				strategy_temp_normal_low =	<4540 30 0 0 0
								 4550 20 1 0 0>;
				strategy_temp_normal_high =	<4540 30 0 0 0
								 4550 22 1 0 0>;
				strategy_temp_warm = <4120 26 1 0 0
								 4130 20 1 0 0>;
			};

			strategy_soc_50_to_75 { /* 56 ~ 75 */
				strategy_temp_little_cold =	<4500 20 1 0 0>;
				strategy_temp_cool = <4490 30 0 0 0
								 4500 20 1 0 0>;
				strategy_temp_little_cool =	<4540 30 0 0 0
								 4550 20 1 0 0>;
				strategy_temp_little_cool_high = <4540 30 0 0 0
								 4550 20 1 0 0>;
				strategy_temp_normal_low = <4540 30 0 0 0
								 4550 20 1 0 0>;
				strategy_temp_normal_high =	<4540 30 0 0 0
								 4550 22 1 0 0>;
				strategy_temp_warm = <4130 20 1 0 0>;
			};

			strategy_soc_75_to_85 { /* 76 ~ 85 */
				strategy_temp_little_cold =	<4500 20 1 0 0>;
				strategy_temp_cool = <4500 20 1 0 0>;
				strategy_temp_little_cool =	<4540 30 0 0 0
								 4550 20 1 0 0>;
				strategy_temp_little_cool_high = <4540 30 0 0 0
								 4550 20 1 0 0>;
				strategy_temp_normal_low = <4540 30 0 0 0
								 4550 20 1 0 0>;
				strategy_temp_normal_high =	<4540 30 0 0 0
								 4550 22 1 0 0>;
				strategy_temp_warm = <4130 20 1 0 0>;
			};

			strategy_soc_85_to_90 {
				strategy_temp_little_cold =	<4500 20 1 0 0>;
				strategy_temp_cool = <4500 20 1 0 0>;
				strategy_temp_little_cool =	<4550 20 1 0 0>;
				strategy_temp_little_cool_high = <4550 20 1 0 0>;
				strategy_temp_normal_low =	<4550 20 1 0 0>;
				strategy_temp_normal_high =	<4550 20 1 0 0>;
				strategy_temp_warm = <4130 20 1 0 0>;
			};
		};
		oplus_sc8547_cp: oplus,sc8547_cp {
			oplus,ic_type = <OPLUS_CHG_IC_CP>;
			oplus,ic_index = <0>;
			oplus,ic_func_group = <&sc8547_cp_groups>;
		};
	};
};

&qupv3_se13_i2c {
	status = "okay";
};

&qupv3_se5_2uart  {
	pinctrl-1 = <&qupv3_se5_2uart_sleep_backup>;
	status = "okay";
};

&tlmm {
	qupv3_se5_2uart_sleep_backup:qupv3_se5_2uart_sleep_backup {
		mux {
			pins = "gpio25", "gpio26";
			function = "gpio";
		};

		config {
			pins = "gpio25", "gpio26";
			drive-strength = <2>;
			bias-disable;
			input-enable;
		};
	};
};

&tlmm {
	charging_inter_active: charging_inter_active {
		mux {
			pins = "gpio125";
			function = "gpio";
		};
		config {
			pins = "gpio125";
			bias-pull-up; /* NO pull */
			drive-strength = <2>; /* 2 MA */
			input-enable;
		};
	};

	charging_inter_sleep: charging_inter_sleep {
		mux {
			pins = "gpio125";
			function = "gpio";
		};
		config {
			pins = "gpio125";
			bias-pull-up; /* NO pull */
			drive-strength = <2>; /* 2 MA */
			input-enable;
		};
	};
};

&pmk8550_gpios {
	svooc_mos_btb_therm {
		svooc_mos_btb_therm_default: svooc_mos_btb_therm_default {
			pins = "gpio2";
			function = "normal"; //normal
			bias-high-impedance;
			bias-disable;
		};
	};
};

&pmiv0104_gpios {
	btb_temp_gpio_default: btb_temp_gpio_default {
		pins = "gpio2";
		function = "normal"; //normal
		bias-high-impedance;
		bias-disable;
	};
};

&pmxr2230_gpios {
	usbtemp_l_gpio_default: usbtemp_l_gpio_default {
		pins = "gpio3"; //GPIO 3
		function = "normal"; //normal
		bias-high-impedance; //DISABLE GPIO3 for ADC
		bias-disable;
	};
	usbtemp_r_gpio_default: usbtemp_r_gpio_default {
		pins = "gpio4"; //GPIO 4
		function = "normal"; //normal
		bias-high-impedance; //DISABLE GPIO4 for ADC
		bias-disable;
	};
	subboard_temp_gpio_default: subboard_temp_gpio_default {
		pins = "gpio7"; //GPIO 7
		function = "normal"; //normal
		bias-high-impedance; //DISABLE GPIO7 for ADC
		bias-disable;
	};
	dpdm_switch_vooc: dpdm_switch_vooc {
		pins = "gpio8";
		function = "normal";
		bias-disable;
		power-source = <1>;
		output-high;
		qcom,drive-strength = <3>;
	};

	dpdm_switch_ufcs: dpdm_switch_ufcs {
		pins = "gpio8";
		function = "normal";
		bias-disable;
		power-source = <1>;
		output-high;
		qcom,drive-strength = <3>;
	};

	dpdm_switch_ap: dpdm_switch_ap {
		pins = "gpio8";
		function = "normal";
		bias-disable;
		power-source = <1>;
		output-low;
		qcom,drive-strength = <3>;
	};

	switch_ctrl_vooc: switch_ctrl_vooc {
		pins = "gpio12";
		function = "normal";
		bias-disable;
		power-source = <1>;
		output-high;
		qcom,drive-strength = <3>;
	};

	switch_ctrl_ufcs: switch_ctrl_ufcs {
		pins = "gpio12";
		function = "normal";
		bias-disable;
		power-source = <1>;
		output-high;
		qcom,drive-strength = <3>;
	};

	switch_ctrl_ap: switch_ctrl_ap {
		pins = "gpio12";
		function = "normal";
		bias-disable;
		power-source = <1>;
		output-low;
		qcom,drive-strength = <3>;
	};
};

&pmk8550_vadc {
	pinctrl-0 = <&svooc_mos_btb_therm_default &subboard_temp_gpio_default>;
	pinctrl-names = "default";

	svooc_mos_btb_therm {
		reg = <PMK8550_ADC5_GEN3_AMUX_THM3_GPIO2_100K_PU>;
		label = "svooc_mos_btb_therm";
		qcom,ratiometric;
		qcom,hw-settle-time = <200>;
		qcom,pre-scaling = <1 1>;
		qcom,adc-tm-type = <1>;
	};
	usb_temp_adc_l {
		reg = <PMXR2230_ADC5_GEN3_AMUX1_GPIO3_100K_PU>;
		label = "usb_temp_adc_l";
		qcom,pre-scaling = <1 1>;
		qcom,ratiometric;
		qcom,hw-settle-time = <200>;
		qcom,scale-fn-type = <OPLUS_ADC_SCALE_HW_CALIB_DEFAULT>;
	};
	usb_temp_adc_r {
		reg = <PMXR2230_ADC5_GEN3_AMUX2_GPIO4_100K_PU>;
		label = "usb_temp_adc_r";
		qcom,pre-scaling = <1 1>;
		qcom,ratiometric;
		qcom,hw-settle-time = <200>;
		qcom,scale-fn-type = <OPLUS_ADC_SCALE_HW_CALIB_DEFAULT>;
	};
	subboard_temp_adc {
		reg = <PMXR2230_ADC5_GEN3_AMUX3_GPIO7_100K_PU>;
		label = "subboard_temp_adc";
		qcom,ratiometric;
		qcom,hw-settle-time = <200>;
		qcom,pre-scaling = <1 1>;
		qcom,adc-tm-type = <1>;
	};

	batt_con_therm_adc {
		reg = <PMIV0104_ADC5_GEN3_AMUX_THM6_GPIO6_100K_PU>;
		label = "batt_con_therm_adc";
		qcom,ratiometric;
		qcom,hw-settle-time = <200>;
		qcom,pre-scaling = <1 1>;
		qcom,adc-tm-type = <0>;
	};
	usb_con_therm_adc {
		reg = <PMIV0104_ADC5_GEN3_AMUX_THM4_USB_THERM_100K_PU>;
		label = "usb_con_therm_adc";
		qcom,ratiometric;
		qcom,hw-settle-time = <200>;
		qcom,pre-scaling = <1 1>;
		qcom,adc-tm-type = <1>;
		qcom,scale-fn-type = <OPLUS_ADC_SCALE_HW_CALIB_THERM_100K_PULLUP>;
	};
};

&thermal_zones {
	svooc_mos_btb_usr {
		polling-delay-passive = <0>;
		polling-delay = <0>;
		thermal-governor = "user_space";
		thermal-sensors = <&pmk8550_vadc PMK8550_ADC5_GEN3_AMUX_THM3_GPIO2_100K_PU>;
		wake-capable-sensor;
		trips {
			active-config0 {
				temperature = <125000>;
				hysteresis = <1000>;
				type = "passive";
			};
		};
	};
	batt-therm {
		polling-delay-passive = <0>;
		polling-delay = <0>;
		thermal-governor = "user_space";
		thermal-sensors = <&pmk8550_vadc PMXR2230_ADC5_GEN3_AMUX3_GPIO7_100K_PU>;
		wake-capable-sensor;
		trips {
			active-config0 {
				temperature = <125000>;
				hysteresis = <1000>;
				type = "passive";
			};
		};
	};
};

&battery_charger {
	io-channels = <&pmk8550_vadc PMXR2230_ADC5_GEN3_AMUX3_GPIO7_100K_PU>,
					<&pmk8550_vadc PMIV0104_ADC5_GEN3_AMUX_THM6_GPIO6_100K_PU>,
					<&pmk8550_vadc PMIV0104_ADC5_GEN3_AMUX_THM4_USB_THERM_100K_PU>;
	io-channel-names = "subboard_temp_adc", "batt_con_therm_adc", "usb_con_therm_adc";
};

&pm8550vs_c_gpios {
	dischg_enable: dischg_enable {
		pins = "gpio4";
		function = "normal";
		bias-disable;
		power-source = <0>;
		output-high;
		qcom,drive-strength = <3>;
	};
	dischg_disable: dischg_disable {
		pins = "gpio4";
		function = "normal";
		bias-disable;
		power-source = <0>;
		output-low;
		qcom,drive-strength = <3>;
	};
};

&soc {
	oplus_chg_plc: oplus,plc_charge {
		compatible = "oplus,plc_charge";
		oplus,plc_soc = <90>;
		oplus,plc_strategy-data = <&buck_simple_strategy>;
		oplus,plc_strategy-names = "default";

		oplus_ufcs_step_strategy: oplus_ufcs_step_strategy {
			oplus,strategy_type = <PLC_STRATEGY_STEP>;
		};

		third_ufcs_simple_strategy: third_ufcs_simple_strategy {
			oplus,strategy_type = <PLC_STRATEGY_SIMPLE>;
			oplus,strategy_data {
				strategy_curr_ma = <1000 1500>;
			};
		};

		pps_simple_strategy: pps_simple_strategy {
			oplus,strategy_type = <PLC_STRATEGY_SIMPLE>;
			oplus,strategy_data {
				strategy_curr_ma = <1000 1500>;
			};
		};

		svooc_simple_strategy: svooc_simple_strategy {
			oplus,strategy_type = <PLC_STRATEGY_SIMPLE>;
			oplus,strategy_data {
				strategy_curr_ma = <1000 1500>;
			};
		};

		vooc_simple_strategy: vooc_simple_strategy {
			oplus,strategy_type = <PLC_STRATEGY_SIMPLE>;
			oplus,strategy_data {
				strategy_curr_ma = <2000 3000>;
			};
		};


		buck_simple_strategy: buck_simple_strategy {
			oplus,strategy_type = <PLC_STRATEGY_SIMPLE>;
		};
	};
};
